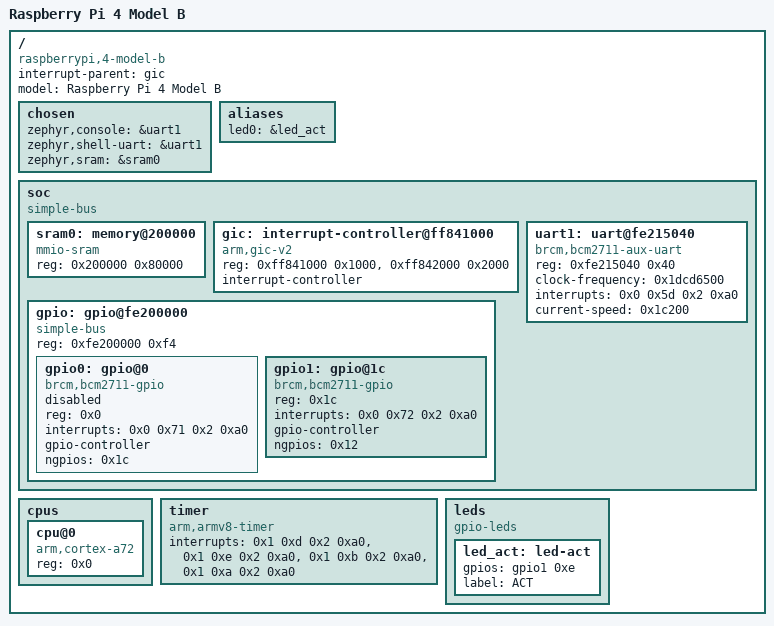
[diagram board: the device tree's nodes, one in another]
/dts-v1/;

/* node '/' defined in zephyr/dts/common/skeleton.dtsi:9 */
/ {
	interrupt-parent = < &gic >;          /* in zephyr/dts/arm64/broadcom/bcm2711.dtsi:25 */
	model = "Raspberry Pi 4 Model B";     /* in zephyr/boards/raspberrypi/rpi_4b/rpi_4b.dts:13 */
	compatible = "raspberrypi,4-model-b",
	             "brcm,bcm2838";          /* in zephyr/boards/raspberrypi/rpi_4b/rpi_4b.dts:14 */
	#address-cells = < 0x1 >;             /* in zephyr/boards/raspberrypi/rpi_4b/rpi_4b.dts:15 */
	#size-cells = < 0x1 >;                /* in zephyr/boards/raspberrypi/rpi_4b/rpi_4b.dts:16 */

	/* node '/chosen' defined in zephyr/dts/common/skeleton.dtsi:13 */
	chosen {
		zephyr,console = &uart1;    /* in zephyr/boards/raspberrypi/rpi_4b/rpi_4b.dts:23 */
		zephyr,shell-uart = &uart1; /* in zephyr/boards/raspberrypi/rpi_4b/rpi_4b.dts:24 */
		zephyr,sram = &sram0;       /* in zephyr/boards/raspberrypi/rpi_4b/rpi_4b.dts:25 */
	};

	/* node '/aliases' defined in zephyr/dts/common/skeleton.dtsi:15 */
	aliases {
		led0 = &led_act; /* in zephyr/boards/raspberrypi/rpi_4b/rpi_4b.dts:19 */
	};

	/* node '/soc' defined in zephyr/dts/arm64/armv8-a.dtsi:10 */
	soc {
		#address-cells = < 0x1 >;  /* in zephyr/dts/arm64/armv8-a.dtsi:11 */
		#size-cells = < 0x1 >;     /* in zephyr/dts/arm64/armv8-a.dtsi:12 */
		compatible = "simple-bus"; /* in zephyr/dts/arm64/armv8-a.dtsi:13 */
		ranges;                    /* in zephyr/dts/arm64/armv8-a.dtsi:14 */

		/* node '/soc/memory@200000' defined in zephyr/dts/arm64/broadcom/bcm2711.dtsi:40 */
		sram0: memory@200000 {
			device_type = "memory";     /* in zephyr/dts/arm64/broadcom/bcm2711.dtsi:41 */
			compatible = "mmio-sram";   /* in zephyr/dts/arm64/broadcom/bcm2711.dtsi:42 */
			reg = < 0x200000 0x80000 >; /* in zephyr/dts/arm64/broadcom/bcm2711.dtsi:43 */
		};

		/* node '/soc/interrupt-controller@ff841000' defined in zephyr/dts/arm64/broadcom/bcm2711.dtsi:46 */
		gic: interrupt-controller@ff841000 {
			compatible = "arm,gic-v2",
			             "arm,gic";      /* in zephyr/dts/arm64/broadcom/bcm2711.dtsi:47 */
			reg = < 0xff841000 0x1000 >,
			      < 0xff842000 0x2000 >; /* in zephyr/dts/arm64/broadcom/bcm2711.dtsi:48 */
			interrupt-controller;        /* in zephyr/dts/arm64/broadcom/bcm2711.dtsi:50 */
			#interrupt-cells = < 0x4 >;  /* in zephyr/dts/arm64/broadcom/bcm2711.dtsi:51 */
			status = "okay";             /* in zephyr/dts/arm64/broadcom/bcm2711.dtsi:52 */
			phandle = < 0x1 >;           /* in zephyr/dts/arm64/broadcom/bcm2711.dtsi:25 */
		};

		/* node '/soc/gpio@fe200000' defined in zephyr/dts/arm64/broadcom/bcm2711.dtsi:55 */
		gpio: gpio@fe200000 {
			compatible = "simple-bus"; /* in zephyr/dts/arm64/broadcom/bcm2711.dtsi:56 */
			reg = < 0xfe200000 0xf4 >; /* in zephyr/dts/arm64/broadcom/bcm2711.dtsi:57 */
			#address-cells = < 0x1 >;  /* in zephyr/dts/arm64/broadcom/bcm2711.dtsi:58 */
			#size-cells = < 0x0 >;     /* in zephyr/dts/arm64/broadcom/bcm2711.dtsi:59 */

			/* node '/soc/gpio@fe200000/gpio@0' defined in zephyr/dts/arm64/broadcom/bcm2711.dtsi:62 */
			gpio0: gpio@0 {
				compatible = "brcm,bcm2711-gpio";   /* in zephyr/dts/arm64/broadcom/bcm2711.dtsi:63 */
				reg = < 0x0 >;                      /* in zephyr/dts/arm64/broadcom/bcm2711.dtsi:64 */
				interrupts = < 0x0 0x71 0x2 0xa0 >; /* in zephyr/dts/arm64/broadcom/bcm2711.dtsi:65 */
				gpio-controller;                    /* in zephyr/dts/arm64/broadcom/bcm2711.dtsi:67 */
				#gpio-cells = < 0x2 >;              /* in zephyr/dts/arm64/broadcom/bcm2711.dtsi:68 */
				ngpios = < 0x1c >;                  /* in zephyr/dts/arm64/broadcom/bcm2711.dtsi:69 */
				status = "disabled";                /* in zephyr/dts/arm64/broadcom/bcm2711.dtsi:70 */
			};

			/* node '/soc/gpio@fe200000/gpio@1c' defined in zephyr/dts/arm64/broadcom/bcm2711.dtsi:74 */
			gpio1: gpio@1c {
				compatible = "brcm,bcm2711-gpio";   /* in zephyr/dts/arm64/broadcom/bcm2711.dtsi:75 */
				reg = < 0x1c >;                     /* in zephyr/dts/arm64/broadcom/bcm2711.dtsi:76 */
				interrupts = < 0x0 0x72 0x2 0xa0 >; /* in zephyr/dts/arm64/broadcom/bcm2711.dtsi:77 */
				gpio-controller;                    /* in zephyr/dts/arm64/broadcom/bcm2711.dtsi:79 */
				#gpio-cells = < 0x2 >;              /* in zephyr/dts/arm64/broadcom/bcm2711.dtsi:80 */
				ngpios = < 0x12 >;                  /* in zephyr/dts/arm64/broadcom/bcm2711.dtsi:81 */
				status = "okay";                    /* in zephyr/boards/raspberrypi/rpi_4b/rpi_4b.dts:39 */
				phandle = < 0x2 >;                  /* in zephyr/boards/raspberrypi/rpi_4b/rpi_4b.dts:32 */
			};
		};

		/* node '/soc/uart@fe215040' defined in zephyr/dts/arm64/broadcom/bcm2711.dtsi:86 */
		uart1: uart@fe215040 {
			compatible = "brcm,bcm2711-aux-uart"; /* in zephyr/dts/arm64/broadcom/bcm2711.dtsi:87 */
			reg = < 0xfe215040 0x40 >;            /* in zephyr/dts/arm64/broadcom/bcm2711.dtsi:88 */
			clock-frequency = < 0x1dcd6500 >;     /* in zephyr/dts/arm64/broadcom/bcm2711.dtsi:89 */
			interrupts = < 0x0 0x5d 0x2 0xa0 >;   /* in zephyr/dts/arm64/broadcom/bcm2711.dtsi:90 */
			status = "okay";                      /* in zephyr/boards/raspberrypi/rpi_4b/rpi_4b.dts:43 */
			current-speed = < 0x1c200 >;          /* in zephyr/boards/raspberrypi/rpi_4b/rpi_4b.dts:44 */
		};
	};

	/* node '/cpus' defined in zephyr/dts/arm64/broadcom/bcm2711.dtsi:14 */
	cpus {
		#address-cells = < 0x1 >; /* in zephyr/dts/arm64/broadcom/bcm2711.dtsi:15 */
		#size-cells = < 0x0 >;    /* in zephyr/dts/arm64/broadcom/bcm2711.dtsi:16 */

		/* node '/cpus/cpu@0' defined in zephyr/dts/arm64/broadcom/bcm2711.dtsi:18 */
		cpu@0 {
			device_type = "cpu";           /* in zephyr/dts/arm64/broadcom/bcm2711.dtsi:19 */
			compatible = "arm,cortex-a72"; /* in zephyr/dts/arm64/broadcom/bcm2711.dtsi:20 */
			reg = < 0x0 >;                 /* in zephyr/dts/arm64/broadcom/bcm2711.dtsi:21 */
		};
	};

	/* node '/timer' defined in zephyr/dts/arm64/broadcom/bcm2711.dtsi:27 */
	timer {
		compatible = "arm,armv8-timer";    /* in zephyr/dts/arm64/broadcom/bcm2711.dtsi:28 */
		interrupts = < 0x1 0xd 0x2 0xa0 >,
		             < 0x1 0xe 0x2 0xa0 >,
		             < 0x1 0xb 0x2 0xa0 >,
		             < 0x1 0xa 0x2 0xa0 >; /* in zephyr/dts/arm64/broadcom/bcm2711.dtsi:29 */
	};

	/* node '/leds' defined in zephyr/boards/raspberrypi/rpi_4b/rpi_4b.dts:28 */
	leds {
		compatible = "gpio-leds"; /* in zephyr/boards/raspberrypi/rpi_4b/rpi_4b.dts:29 */

		/* node '/leds/led-act' defined in zephyr/boards/raspberrypi/rpi_4b/rpi_4b.dts:31 */
		led_act: led-act {
			gpios = < &gpio1 0xe 0x0 >; /* in zephyr/boards/raspberrypi/rpi_4b/rpi_4b.dts:32 */
			label = "ACT";              /* in zephyr/boards/raspberrypi/rpi_4b/rpi_4b.dts:33 */
		};
	};
};
